# ing920 register map
Vendor: INGChips; Series: ing920xx; File version: 1.0
CPU: CM3 r2p1, little endian, no MPU, no FPU, 2 interrupt priority bits
Registers are 32-bit, read-write, reset 0x0 unless marked. A register's access mark holds for its fields unless they carry their own. Offsets are from the block's base; [hi:lo] are bit positions; {n}, {i} and the like mark numbered series.

## TRNG
Base 0x40007000
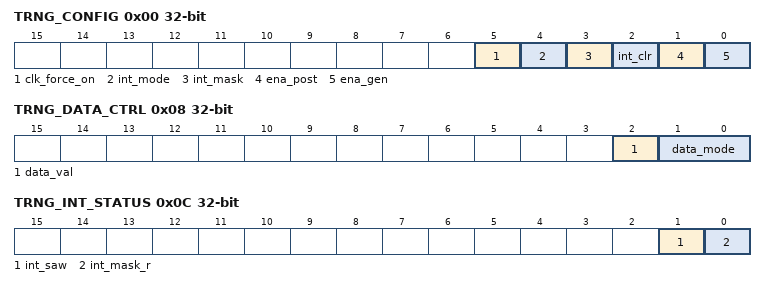
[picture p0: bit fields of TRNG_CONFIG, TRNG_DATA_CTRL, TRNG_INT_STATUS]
0x00 TRNG_CONFIG — reg description:
  [5] clk_force_on — reg description:
  [4] int_mode — reg description:
  [3] int_mask — reg description:
  [2] int_clr — reg description:
  [1] ena_post — reg description:
  [0] ena_gen — reg description:
0x04 TRNG_BIT_SEL — reg description:
  [18:0] bit_sel
0x08 TRNG_DATA_CTRL — reg description:
  [2] data_val — reg description:
  [1:0] data_mode — reg description:
0x0C TRNG_INT_STATUS — reg description:
  [1] int_saw — reg description:
  [0] int_mask_r — reg description:
0x10 TRNG_DATA — reg description:

## DMA
Base 0x4000C000
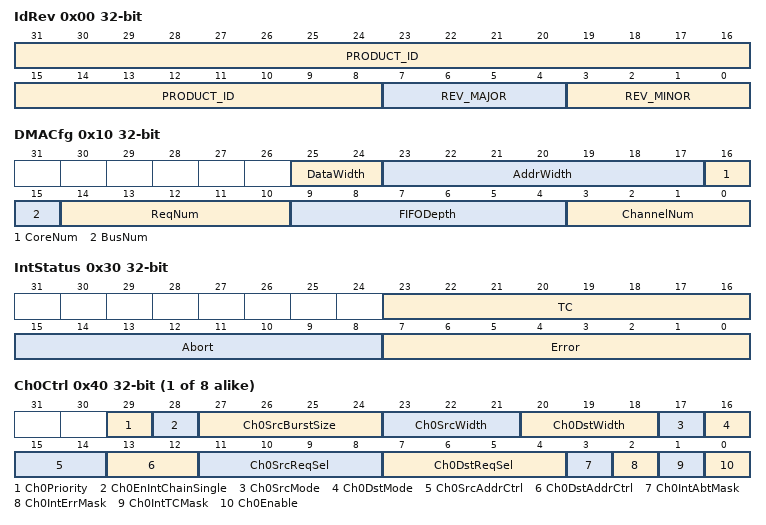
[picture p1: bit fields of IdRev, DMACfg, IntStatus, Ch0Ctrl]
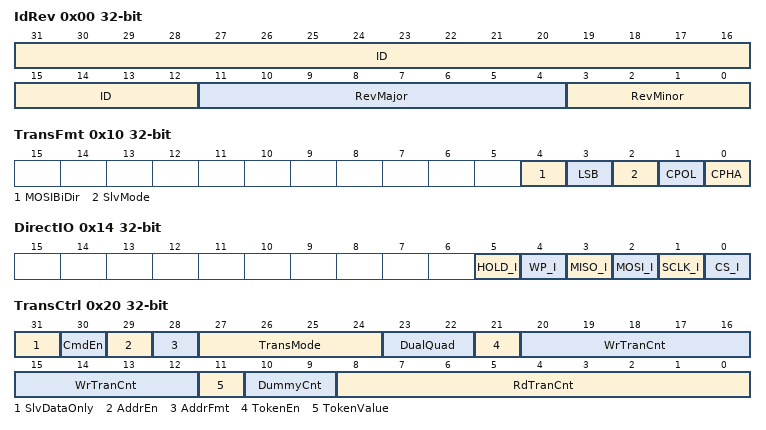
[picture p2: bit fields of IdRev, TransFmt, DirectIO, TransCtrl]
0x00 IdRev — reg description:
  [31:8] PRODUCT_ID — reg description:
  [7:4] REV_MAJOR — reg description:
  [3:0] REV_MINOR — reg description:
0x04 IdMisc — reg description:
0x10 DMACfg — reg description:
  [25:24] DataWidth — reg description:
  [23:17] AddrWidth — reg description:
  [16] CoreNum — reg description:
  [15] BusNum — reg description:
  [14:10] ReqNum — reg description:
  [9:4] FIFODepth — reg description:
  [3:0] ChannelNum — reg description:
0x20 DMACtrl — reg description:
  [0] Reset
0x24 ChAbort — reg description:
  [7:0] ChAbort
0x30 IntStatus — reg description:
  [23:16] TC — reg description:
  [15:8] Abort — reg description:
  [7:0] Error — reg description:
0x34 ChEN — reg description:
  [7:0] ChEN
{0x40+0x20*i} Ch{i}Ctrl (i=0..7) — reg description:
  [29] Ch{i}Priority — reg description:
  [28] Ch{i}EnIntChainSingle — reg description:
  [27:24] Ch{i}SrcBurstSize — reg description:
  [23:21] Ch{i}SrcWidth — reg description:
  [20:18] Ch{i}DstWidth — reg description:
  [17] Ch{i}SrcMode — reg description:
  [16] Ch{i}DstMode — reg description:
  [15:14] Ch{i}SrcAddrCtrl — reg description:
  [13:12] Ch{i}DstAddrCtrl — reg description:
  [11:8] Ch{i}SrcReqSel — reg description:
  [7:4] Ch{i}DstReqSel — reg description:
  [3] Ch{i}IntAbtMask — reg description:
  [2] Ch{i}IntErrMask — reg description:
  [1] Ch{i}IntTCMask — reg description:
  [0] Ch{i}Enable — reg description:
{0x44+0x20*i} Ch{i}TranSize (i=0..7) — reg description:
{0x48+0x20*i} Ch{i}SrcAddr (i=0..7) — reg description:
{0x50+0x20*i} Ch{i}DstAddr (i=0..7) — reg description:
{0x58+0x20*i} Ch{i}LLPointer (i=0..7) — reg description:

## QSPI
Base 0x40160000
Same registers: APBSPI 0x4000E000
0x00 IdRev — reg description:
  [31:12] ID — reg description:
  [11:4] RevMajor — reg description:
  [3:0] RevMinor — reg description:
0x10 TransFmt — reg description:
  [4] MOSIBiDir — reg description:
  [3] LSB — reg description:
  [2] SlvMode — reg description:
  [1] CPOL — reg description:
  [0] CPHA — reg description:
0x14 DirectIO — reg description:
  [5] HOLD_I — reg description:
  [4] WP_I — reg description:
  [3] MISO_I — reg description:
  [2] MOSI_I — reg description:
  [1] SCLK_I — reg description:
  [0] CS_I — reg description:
0x20 TransCtrl — reg description:
  [31] SlvDataOnly — reg description:
  [30] CmdEn — reg description:
  [29] AddrEn — reg description:
  [28] AddrFmt — reg description:
  [27:24] TransMode — reg description:
  [23:22] DualQuad — reg description:
  [21] TokenEn — reg description:
  [20:12] WrTranCnt — reg description:
  [11] TokenValue — reg description:
  [10:9] DummyCnt — reg description:
  [8:0] RdTranCnt — reg description:
0x24 Cmd — reg description:
  [7:0] CMD
0x28 Addr — reg description:
0x2C Data — reg description:
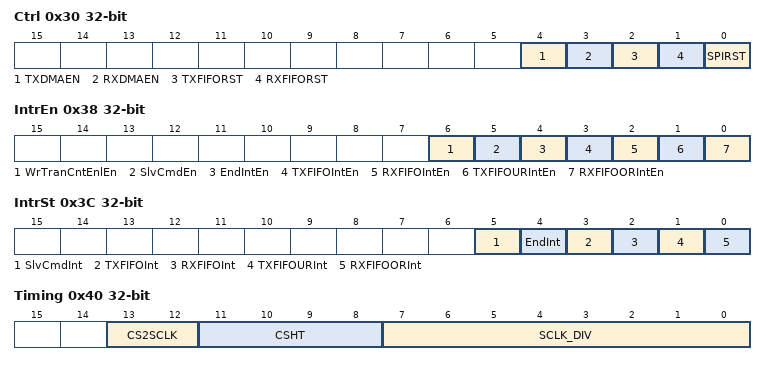
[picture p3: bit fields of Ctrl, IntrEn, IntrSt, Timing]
0x30 Ctrl — reg description:
  [4] TXDMAEN — reg description:
  [3] RXDMAEN — reg description:
  [2] TXFIFORST — reg description:
  [1] RXFIFORST — reg description:
  [0] SPIRST — reg description:
0x34 Status — reg description:
  [0] SPIActive
0x38 IntrEn — reg description:
  [6] WrTranCntEnlEn — reg description:
  [5] SlvCmdEn — reg description:
  [4] EndIntEn — reg description:
  [3] TXFIFOIntEn — reg description:
  [2] RXFIFOIntEn — reg description:
  [1] TXFIFOURIntEn — reg description:
  [0] RXFIFOORIntEn — reg description:
0x3C IntrSt — reg description:
  [5] SlvCmdInt — reg description:
  [4] EndInt — reg description:
  [3] TXFIFOInt — reg description:
  [2] RXFIFOInt — reg description:
  [1] TXFIFOURInt — reg description:
  [0] RXFIFOORInt — reg description:
0x40 Timing — reg description:
  [13:12] CS2SCLK — reg description:
  [11:8] CSHT — reg description:
  [7:0] SCLK_DIV — reg description:
0x50 MemCtrl — reg description:
  [3:0] MemRdCmd
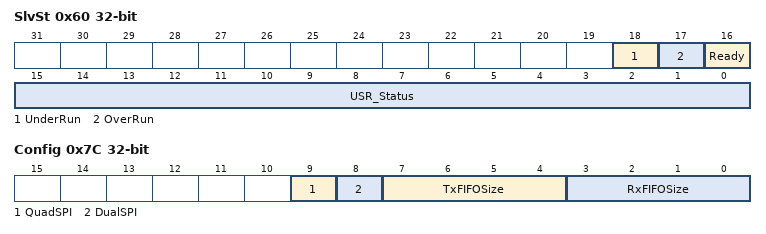
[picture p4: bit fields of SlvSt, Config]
0x60 SlvSt — reg description:
  [18] UnderRun — reg description:
  [17] OverRun — reg description:
  [16] Ready — reg description:
  [15:0] USR_Status — reg description:
0x64 SlvDataCnt — reg description:
  [9:0] RCnt
0x7C Config — reg description:
  [9] QuadSPI — reg description:
  [8] DualSPI — reg description:
  [7:4] TxFIFOSize — reg description:
  [3:0] RxFIFOSize — reg description:

## Notices in the file
Copyright (c) 2022, INGChips All rights reserved.
Redistribution and use in source and binary forms, with or without
modification, are permitted provided that the following conditions are met:
1. Redistributions of source code must retain the above copyright notice, this
list of conditions and the following disclaimer.
2. Redistributions in binary form must reproduce the above copyright
notice, this list of conditions and the following disclaimer in the
documentation and/or other materials provided with the distribution.
3. Neither the name of Nordic Semiconductor ASA nor the names of its
contributors may be used to endorse or promote products derived from this
software without specific prior written permission.
THIS SOFTWARE IS PROVIDED BY THE COPYRIGHT HOLDERS AND CONTRIBUTORS "AS IS"
AND ANY EXPRESS OR IMPLIED WARRANTIES, INCLUDING, BUT NOT LIMITED TO, THE
IMPLIED WARRANTIES OF MERCHANTABILITY, AND FITNESS FOR A PARTICULAR PURPOSE
ARE DISCLAIMED. IN NO EVENT SHALL NORDIC SEMICONDUCTOR ASA OR CONTRIBUTORS BE
LIABLE FOR ANY DIRECT, INDIRECT, INCIDENTAL, SPECIAL, EXEMPLARY, OR
CONSEQUENTIAL DAMAGES (INCLUDING, BUT NOT LIMITED TO, PROCUREMENT OF
SUBSTITUTE GOODS OR SERVICES; LOSS OF USE, DATA, OR PROFITS; OR BUSINESS
INTERRUPTION) HOWEVER CAUSED AND ON ANY THEORY OF LIABILITY, WHETHER IN
CONTRACT, STRICT LIABILITY, OR TORT (INCLUDING NEGLIGENCE OR OTHERWISE)
ARISING IN ANY WAY OUT OF THE USE OF THIS SOFTWARE, EVEN IF ADVISED OF THE
POSSIBILITY OF SUCH DAMAGE.
